VERSION "fiat_500e BDU/BPCM TX - z inwentaryzacji FW @0x800ecaa0 + log weryfikacja"

NS_ :

BS_:

BU_: BPCM VEH

BO_ 64 BPCM_040_nr2: 8 BPCM
 SG_ Raw_040 : 0|64@1+ (1,0) [0|0] "" VEH

BO_ 224 BPCM_0E0_nr15: 8 BPCM
 SG_ Raw_0E0 : 0|64@1+ (1,0) [0|0] "" VEH

BO_ 263 BPCM_107_nr5: 8 BPCM
 SG_ Raw_107 : 0|64@1+ (1,0) [0|0] "" VEH

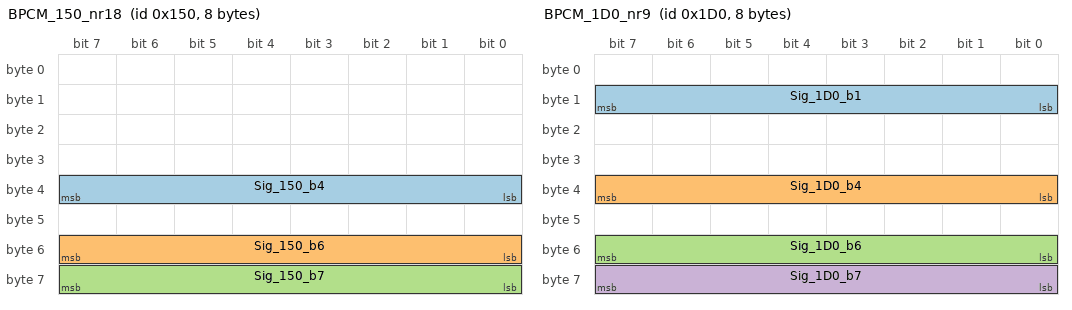
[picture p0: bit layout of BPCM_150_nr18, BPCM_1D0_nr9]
BO_ 336 BPCM_150_nr18: 8 BPCM
 SG_ Sig_150_b4 : 32|8@1+ (1,0) [0|255] "" VEH
 SG_ Sig_150_b6 : 48|8@1+ (1,0) [0|255] "" VEH
 SG_ Sig_150_b7 : 56|8@1+ (1,0) [0|255] "" VEH

BO_ 337 BPCM_151_nr23: 8 BPCM
 SG_ Sig_151_b3 : 24|8@1+ (1,0) [0|255] "" VEH

BO_ 464 BPCM_1D0_nr9: 8 BPCM
 SG_ Sig_1D0_b1 : 8|8@1+ (1,0) [0|255] "" VEH
 SG_ Sig_1D0_b4 : 32|8@1+ (1,0) [0|255] "" VEH
 SG_ Sig_1D0_b6 : 48|8@1+ (1,0) [0|255] "" VEH
 SG_ Sig_1D0_b7 : 56|8@1+ (1,0) [0|255] "" VEH

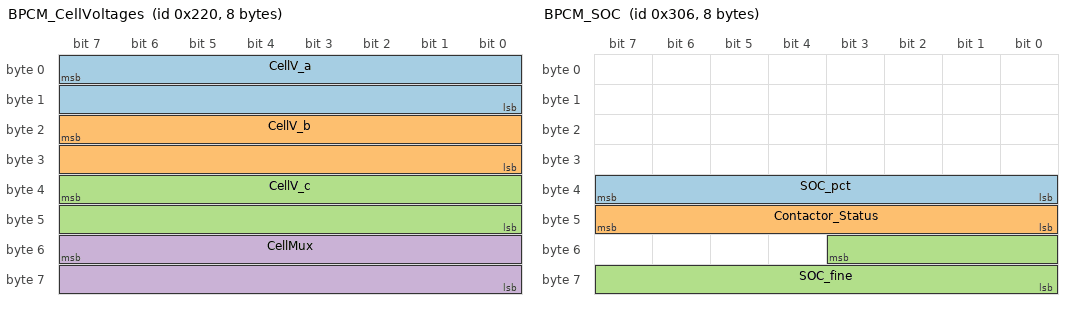
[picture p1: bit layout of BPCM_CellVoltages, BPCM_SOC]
BO_ 544 BPCM_CellVoltages: 8 BPCM
 SG_ CellV_a : 7|16@0+ (1,0) [0|65535] "mV" VEH
 SG_ CellV_b : 23|16@0+ (1,0) [0|65535] "mV" VEH
 SG_ CellV_c : 39|16@0+ (1,0) [0|65535] "mV" VEH
 SG_ CellMux : 55|16@0+ (1,0) [0|65535] "" VEH

BO_ 707 BPCM_2C3: 8 BPCM
 SG_ Sig_2C3_b5 : 40|8@1+ (1,0) [0|255] "" VEH
 SG_ Sig_2C3_b7 : 56|8@1+ (1,0) [0|255] "" VEH

BO_ 708 BPCM_2C4: 8 BPCM
 SG_ Raw_2C4 : 0|64@1+ (1,0) [0|0] "" VEH

BO_ 710 BPCM_2C6: 8 BPCM
 SG_ Raw_2C6 : 0|64@1+ (1,0) [0|0] "" VEH

BO_ 770 BPCM_302_nr81: 8 BPCM
 SG_ Raw_302 : 0|64@1+ (1,0) [0|0] "" VEH

BO_ 773 BPCM_305: 8 BPCM
 SG_ Raw_305 : 0|64@1+ (1,0) [0|0] "" VEH

BO_ 774 BPCM_SOC: 8 BPCM
 SG_ SOC_pct : 32|8@1+ (0.3922,0) [0|100] "%" VEH
 SG_ Contactor_Status : 40|8@1+ (1,0) [0|255] "" VEH
 SG_ SOC_fine : 51|12@0+ (0.02451,0) [0|100] "%" VEH

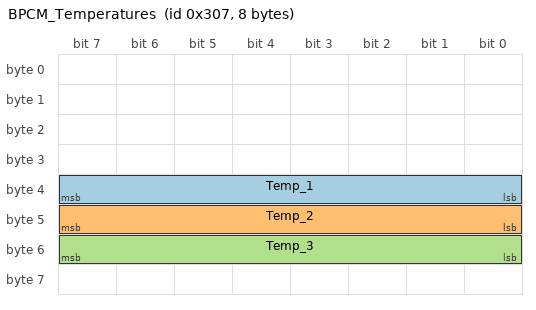
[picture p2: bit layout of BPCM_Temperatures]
BO_ 775 BPCM_Temperatures: 8 BPCM
 SG_ Temp_1 : 32|8@1+ (1,-40) [-40|215] "degC" VEH
 SG_ Temp_2 : 40|8@1+ (1,-40) [-40|215] "degC" VEH
 SG_ Temp_3 : 48|8@1+ (1,-40) [-40|215] "degC" VEH

BO_ 786 BPCM_312_nr24: 8 BPCM
 SG_ Raw_312 : 0|64@1+ (1,0) [0|0] "" VEH

BO_ 850 BPCM_352_nr6: 8 BPCM
 SG_ Raw_352 : 0|64@1+ (1,0) [0|0] "" VEH

BO_ 851 BPCM_353_nr20: 8 BPCM
 SG_ Raw_353 : 0|64@1+ (1,0) [0|0] "" VEH

BO_ 852 BPCM_354_nr21: 8 BPCM
 SG_ Raw_354 : 0|64@1+ (1,0) [0|0] "" VEH

BO_ 854 BPCM_356_nr14: 8 BPCM
 SG_ Raw_356 : 0|64@1+ (1,0) [0|0] "" VEH

BO_ 1000 BPCM_3E8_nr22: 8 BPCM
 SG_ Raw_3E8 : 0|64@1+ (1,0) [0|0] "" VEH

BO_ 1002 BPCM_3EA_nr16: 8 BPCM
 SG_ Raw_3EA : 0|64@1+ (1,0) [0|0] "" VEH

BO_ 1003 BPCM_3EB_nr17: 8 BPCM
 SG_ Raw_3EB : 0|64@1+ (1,0) [0|0] "" VEH

BO_ 1004 BPCM_3EC_nr3: 8 BPCM
 SG_ Raw_3EC : 0|64@1+ (1,0) [0|0] "" VEH

BO_ 1005 BPCM_3ED: 8 BPCM
 SG_ Raw_3ED : 0|64@1+ (1,0) [0|0] "" VEH

BO_ 1281 BPCM_CellData_501: 8 BPCM
 SG_ Raw_501 : 0|64@1+ (1,0) [0|0] "" VEH

BO_ 1282 BPCM_CellData_502: 8 BPCM
 SG_ Raw_502 : 0|64@1+ (1,0) [0|0] "" VEH

BO_ 1283 BPCM_CellData_503: 8 BPCM
 SG_ Raw_503 : 0|64@1+ (1,0) [0|0] "" VEH

BO_ 1284 BPCM_CellData_504: 8 BPCM
 SG_ Raw_504 : 0|64@1+ (1,0) [0|0] "" VEH

BO_ 1285 BPCM_CellData_505: 8 BPCM
 SG_ Raw_505 : 0|64@1+ (1,0) [0|0] "" VEH

BO_ 1286 BPCM_CellData_506: 8 BPCM
 SG_ Raw_506 : 0|64@1+ (1,0) [0|0] "" VEH

BO_ 1287 BPCM_CellData_507: 8 BPCM
 SG_ Raw_507 : 0|64@1+ (1,0) [0|0] "" VEH

BO_ 1288 BPCM_CellData_508: 8 BPCM
 SG_ Raw_508 : 0|64@1+ (1,0) [0|0] "" VEH

BO_ 1289 BPCM_CellData_509: 8 BPCM
 SG_ Raw_509 : 0|64@1+ (1,0) [0|0] "" VEH

BO_ 1296 BPCM_CellData_510: 8 BPCM
 SG_ Raw_510 : 0|64@1+ (1,0) [0|0] "" VEH

BO_ 1297 BPCM_CellData_511: 8 BPCM
 SG_ Raw_511 : 0|64@1+ (1,0) [0|0] "" VEH

BO_ 1298 BPCM_CellData_512: 8 BPCM
 SG_ Raw_512 : 0|64@1+ (1,0) [0|0] "" VEH

BO_ 1299 BPCM_CellData_513: 8 BPCM
 SG_ Raw_513 : 0|64@1+ (1,0) [0|0] "" VEH

BO_ 1300 BPCM_CellData_514: 8 BPCM
 SG_ Raw_514 : 0|64@1+ (1,0) [0|0] "" VEH

BO_ 1301 BPCM_CellData_515: 8 BPCM
 SG_ Raw_515 : 0|64@1+ (1,0) [0|0] "" VEH

BO_ 1302 BPCM_CellData_516: 8 BPCM
 SG_ Raw_516 : 0|64@1+ (1,0) [0|0] "" VEH

BO_ 1303 BPCM_CellData_517: 8 BPCM
 SG_ Raw_517 : 0|64@1+ (1,0) [0|0] "" VEH

BO_ 1304 BPCM_CellData_518: 8 BPCM
 SG_ Raw_518 : 0|64@1+ (1,0) [0|0] "" VEH

BO_ 1305 BPCM_CellData_519: 8 BPCM
 SG_ Raw_519 : 0|64@1+ (1,0) [0|0] "" VEH

BO_ 1312 BPCM_CellData_520: 8 BPCM
 SG_ Raw_520 : 0|64@1+ (1,0) [0|0] "" VEH

BO_ 1313 BPCM_CellData_521: 8 BPCM
 SG_ Raw_521 : 0|64@1+ (1,0) [0|0] "" VEH

BO_ 1314 BPCM_CellData_522: 8 BPCM
 SG_ Raw_522 : 0|64@1+ (1,0) [0|0] "" VEH

BO_ 1315 BPCM_CellData_523: 8 BPCM
 SG_ Raw_523 : 0|64@1+ (1,0) [0|0] "" VEH

BO_ 1316 BPCM_CellData_524: 8 BPCM
 SG_ Raw_524 : 0|64@1+ (1,0) [0|0] "" VEH

BO_ 1317 BPCM_CellData_525: 8 BPCM
 SG_ Raw_525 : 0|64@1+ (1,0) [0|0] "" VEH

BO_ 1318 BPCM_CellData_526: 8 BPCM
 SG_ Raw_526 : 0|64@1+ (1,0) [0|0] "" VEH

BO_ 1319 BPCM_CellData_527: 8 BPCM
 SG_ Raw_527 : 0|64@1+ (1,0) [0|0] "" VEH

BO_ 1320 BPCM_CellData_528: 8 BPCM
 SG_ Raw_528 : 0|64@1+ (1,0) [0|0] "" VEH

BO_ 1321 BPCM_CellData_529: 8 BPCM
 SG_ Raw_529 : 0|64@1+ (1,0) [0|0] "" VEH

BO_ 1328 BPCM_CellData_530: 8 BPCM
 SG_ Raw_530 : 0|64@1+ (1,0) [0|0] "" VEH

BO_ 1329 BPCM_CellData_531: 8 BPCM
 SG_ Raw_531 : 0|64@1+ (1,0) [0|0] "" VEH

BO_ 1330 BPCM_CellData_532: 8 BPCM
 SG_ Raw_532 : 0|64@1+ (1,0) [0|0] "" VEH

BO_ 1331 BPCM_CellData_533: 8 BPCM
 SG_ Raw_533 : 0|64@1+ (1,0) [0|0] "" VEH

BO_ 1332 BPCM_CellData_534: 8 BPCM
 SG_ Raw_534 : 0|64@1+ (1,0) [0|0] "" VEH

BO_ 1333 BPCM_CellData_535: 8 BPCM
 SG_ Raw_535 : 0|64@1+ (1,0) [0|0] "" VEH

BO_ 1334 BPCM_CellData_536: 8 BPCM
 SG_ Raw_536 : 0|64@1+ (1,0) [0|0] "" VEH

BO_ 1335 BPCM_CellData_537: 8 BPCM
 SG_ Raw_537 : 0|64@1+ (1,0) [0|0] "" VEH

BO_ 1336 BPCM_CellData_538: 8 BPCM
 SG_ Raw_538 : 0|64@1+ (1,0) [0|0] "" VEH

BO_ 1337 BPCM_CellData_539: 8 BPCM
 SG_ Raw_539 : 0|64@1+ (1,0) [0|0] "" VEH

BO_ 1344 BPCM_CellData_540: 8 BPCM
 SG_ Raw_540 : 0|64@1+ (1,0) [0|0] "" VEH

BO_ 1345 BPCM_CellData_541: 8 BPCM
 SG_ Raw_541 : 0|64@1+ (1,0) [0|0] "" VEH

BO_ 1346 BPCM_CellData_542: 8 BPCM
 SG_ Raw_542 : 0|64@1+ (1,0) [0|0] "" VEH

BO_ 1347 BPCM_CellData_543: 8 BPCM
 SG_ Raw_543 : 0|64@1+ (1,0) [0|0] "" VEH

BO_ 1348 BPCM_CellData_544: 8 BPCM
 SG_ Raw_544 : 0|64@1+ (1,0) [0|0] "" VEH

BO_ 1349 BPCM_CellData_545: 8 BPCM
 SG_ Raw_545 : 0|64@1+ (1,0) [0|0] "" VEH

BO_ 1350 BPCM_CellData_546: 8 BPCM
 SG_ Raw_546 : 0|64@1+ (1,0) [0|0] "" VEH

BO_ 1351 BPCM_CellData_547: 8 BPCM
 SG_ Raw_547 : 0|64@1+ (1,0) [0|0] "" VEH

BO_ 1352 BPCM_CellData_548: 8 BPCM
 SG_ Raw_548 : 0|64@1+ (1,0) [0|0] "" VEH

BO_ 1353 BPCM_CellData_549: 8 BPCM
 SG_ Raw_549 : 0|64@1+ (1,0) [0|0] "" VEH

BO_ 1360 BPCM_CellData_550: 8 BPCM
 SG_ Raw_550 : 0|64@1+ (1,0) [0|0] "" VEH

BO_ 1361 BPCM_CellData_551: 8 BPCM
 SG_ Raw_551 : 0|64@1+ (1,0) [0|0] "" VEH

BO_ 1362 BPCM_CellData_552: 8 BPCM
 SG_ Raw_552 : 0|64@1+ (1,0) [0|0] "" VEH

BO_ 1363 BPCM_CellData_553: 8 BPCM
 SG_ Raw_553 : 0|64@1+ (1,0) [0|0] "" VEH

BO_ 1364 BPCM_CellData_554: 8 BPCM
 SG_ Raw_554 : 0|64@1+ (1,0) [0|0] "" VEH

BO_ 1365 BPCM_CellData_555: 8 BPCM
 SG_ Raw_555 : 0|64@1+ (1,0) [0|0] "" VEH

BO_ 1599 Diag_63F: 8 BPCM
 SG_ Raw_63F : 0|64@1+ (1,0) [0|0] "" VEH

BO_ 1622 BPCM_656_nr0: 8 BPCM
 SG_ Raw_656 : 0|64@1+ (1,0) [0|0] "" VEH

BO_ 2031 UDS_Resp: 8 BPCM
 SG_ Raw_7EF : 0|64@1+ (1,0) [0|0] "" VEH

CM_ BO_ 224 "rest: 00 00 00 00 00 00 00 00";
CM_ BO_ 263 "rest: 00 00 00 00 00 00 00 00";
CM_ BO_ 336 "rest: 00 14 00 87 E2 28 50 B8";
CM_ BO_ 337 "rest: 07 23 88 B5 00 00 00 00";
CM_ BO_ 464 "rest: 3E 30 88 08 28 00 80 33";
CM_ BO_ 544 "rest: 0F 89 0F 92 0F 82 0B 70";
CM_ BO_ 707 "rest: 00 00 09 A7 09 B8 09 AF";
CM_ BO_ 708 "rest: 00 00 00 00 00 00 00 01";
CM_ BO_ 710 "rest: 00 5D 00 00 00 5E 00 00";
CM_ BO_ 773 "rest: 00 00 00 00 00 00 00 7E";
CM_ BO_ 774 "rest: 00 00 D9 F2 D6 D2 0D 62";
CM_ BO_ 775 "rest: 00 00 00 00 3D 3E 3D 00";
CM_ BO_ 786 "rest: 00 00 00 00 00 00 00 00";
CM_ BO_ 850 "rest: 00 00 00 00 00 00 00 00";
CM_ BO_ 851 "rest: 00 00 00 00 04 5F 00 00";
CM_ BO_ 852 "rest: 00 EA 5F 0A 10 A2 0A F0";
CM_ BO_ 854 "rest: 00 00 00 00 00 FF 0B A4";
CM_ BO_ 1000 "rest: 00 00 00 01 C2 00 00 02";
CM_ BO_ 1002 "rest: FF FF FF FF FF 00 00 00";
CM_ BO_ 1003 "rest: FE FF FF 16 00 00 00 00";
CM_ BO_ 1004 "rest: 03 FF 03 FF 03 FF FF 00";
CM_ BO_ 1005 "rest: FF FF 78 FF FF 7F 00 00";
